# PIC32MZ2025DAR176 device description
Architecture: MIPS; Family: PIC32MZDA; Series: PIC32MZ
Registers are 32-bit, read-write, no defined reset value unless marked. A register's access mark holds for its fields unless they carry their own. Offsets are from the block's base; [hi:lo] are bit positions; {n}, {i} and the like mark numbered series; 'fields as' and 'values as' point back to an identical list.

## DDR
Instances: DDR 0x1f8e8000 in periph_indep
0x00 DDRTSEL — DDR Target Select Register
  [7:0] TSEL
0x04 DDRMINLIM — DDR Minimum Burst Limit Register
  [4:0] MINLIMIT
0x08 DDRRQPER — DDR Request Period Register
  [7:0] RQPER
0x0C DDRMINCMD — DDR Minimum Command Register
  [7:0] MINCMD
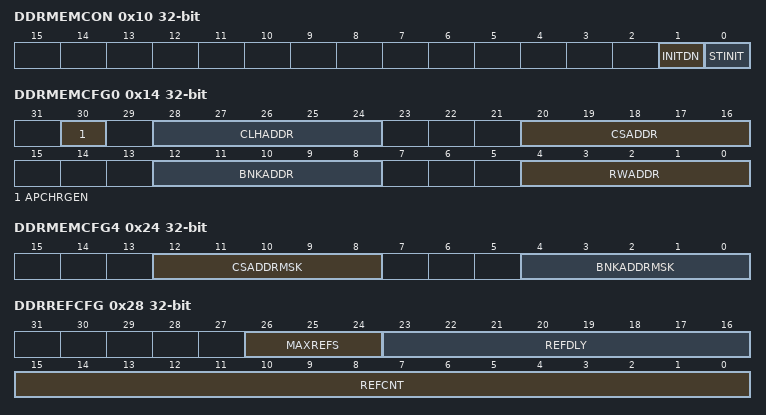
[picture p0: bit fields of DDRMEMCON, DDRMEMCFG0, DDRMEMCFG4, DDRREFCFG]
0x10 DDRMEMCON — DDR Memory Control Register
  [1] INITDN — Memory Initialize Done bit
    1=All commands have been issued; the controller is enabled for regular operation; 0=Controller not enabled for regular operation
  [0] STINIT — Memory Initialize Start bit
    1=Start memory initialization; 0=Do not start memory initialization
0x14 DDRMEMCFG0 — DDR Memory Configuration Register 0
  [30] APCHRGEN — Automatic Precharge Enable bit
    1=Issue an auto-precharged command; 0=Do not issue an auto-precharged command
  [28:24] CLHADDR
  [20:16] CSADDR
  [12:8] BNKADDR
  [4:0] RWADDR
0x18 DDRMEMCFG1 — DDR Memory Configuration Register 1
  [12:0] RWADDRMSK
0x1C DDRMEMCFG2 — DDR Memory Configuration Register 2
  [12:0] CLADDRHMSK
0x20 DDRMEMCFG3 — DDR Memory Configuration Register 3
  [12:0] CLADDRLMSK
0x24 DDRMEMCFG4 — DDR Memory Configuration Register 4
  [12:8] CSADDRMSK, [4:0] BNKADDRMSK
0x28 DDRREFCFG — DDR Refresh Configuration Register
  [26:24] MAXREFS, [23:16] REFDLY, [15:0] REFCNT
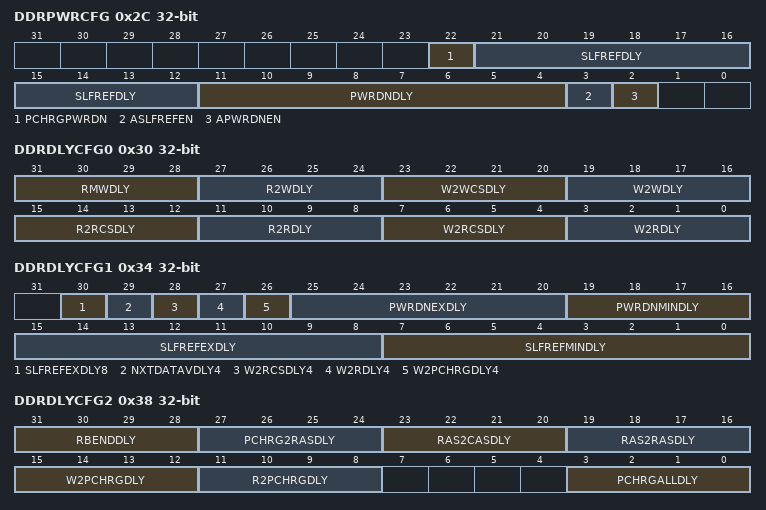
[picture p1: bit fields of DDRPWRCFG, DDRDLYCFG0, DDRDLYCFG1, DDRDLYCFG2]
0x2C DDRPWRCFG — DDR Power Configuration Register
  [22] PCHRGPWRDN — Precharge Power Down Only bit
    1=Allow automatic entry into Precharge Power Down mode; 0=Do not allow automatic entry into Precharge Power Down mode
  [21:12] SLFREFDLY — Self Refresh Delay bits
    0x1ff=2111452 clocks; 1=1024 clocks
  [11:4] PWRDNDLY — Refresh Count bits
    255=1020 clocks; 1=4 clocks
  [3] ASLFREFEN — Automatic Self Refresh Enable bit
    1=Allow automatic entry into Self Refresh mode; 0=Do not allow automatic entry into Self Refresh mode
  [2] APWRDNEN — Automatic Power Down Enable bit
    1=Allow automatic entry into Power Down mode; 0=Do not allow automatic entry into Power Down mode
0x30 DDRDLYCFG0 — DDR Delay Configuration Register 0
  [31:28] RMWDLY, [27:24] R2WDLY, [23:20] W2WCSDLY, [19:16] W2WDLY, [15:12] R2RCSDLY, [11:8] R2RDLY, [7:4] W2RCSDLY, [3:0] W2RDLY
0x34 DDRDLYCFG1 — DDR Delay Configuration Register 1
  [30] SLFREFEXDLY8, [29] NXTDATAVDLY4, [28] W2RCSDLY4, [27] W2RDLY4, [26] W2PCHRGDLY4, [25:20] PWRDNEXDLY, [19:16] PWRDNMINDLY, [15:8] SLFREFEXDLY, [7:0] SLFREFMINDLY
0x38 DDRDLYCFG2 — DDR Delay Configuration Register 2
  [31:28] RBENDDLY, [27:24] PCHRG2RASDLY, [23:20] RAS2CASDLY, [19:16] RAS2RASDLY, [15:12] W2PCHRGDLY, [11:8] R2PCHRGDLY, [3:0] PCHRGALLDLY
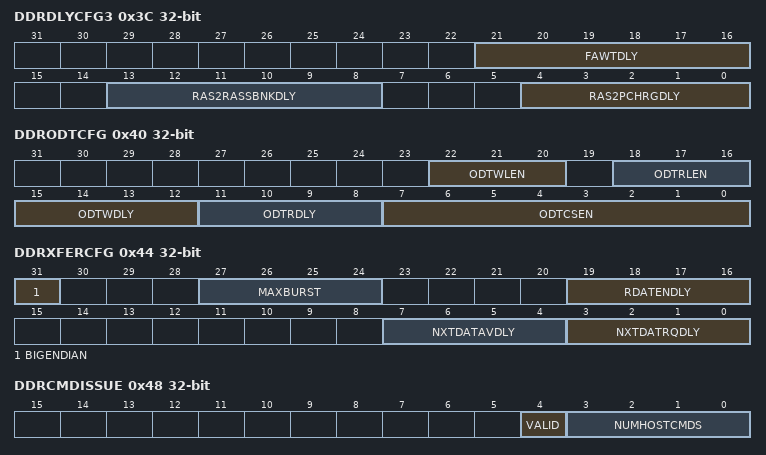
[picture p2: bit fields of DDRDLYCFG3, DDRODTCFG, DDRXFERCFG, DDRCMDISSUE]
0x3C DDRDLYCFG3 — DDR Delay Configuration Register 3
  [21:16] FAWTDLY, [13:8] RAS2RASSBNKDLY, [4:0] RAS2PCHRGDLY
0x40 DDRODTCFG — DDR On-Die Termination Configuration Register
  [22:20] ODTWLEN, [18:16] ODTRLEN, [15:12] ODTWDLY, [11:8] ODTRDLY, [7:0] ODTCSEN
0x44 DDRXFERCFG — DDR Transfer Configuration Register
  [31] BIGENDIAN — Big Endian bit
    1=Data is big endian format; 0=Data is little endian format
  [27:24] MAXBURST
  [19:16] RDATENDLY
  [7:4] NXTDATAVDLY
  [3:0] NXTDATRQDLY
0x48 DDRCMDISSUE — DDR Command Issue Register
  [4] VALID, [3:0] NUMHOSTCMDS
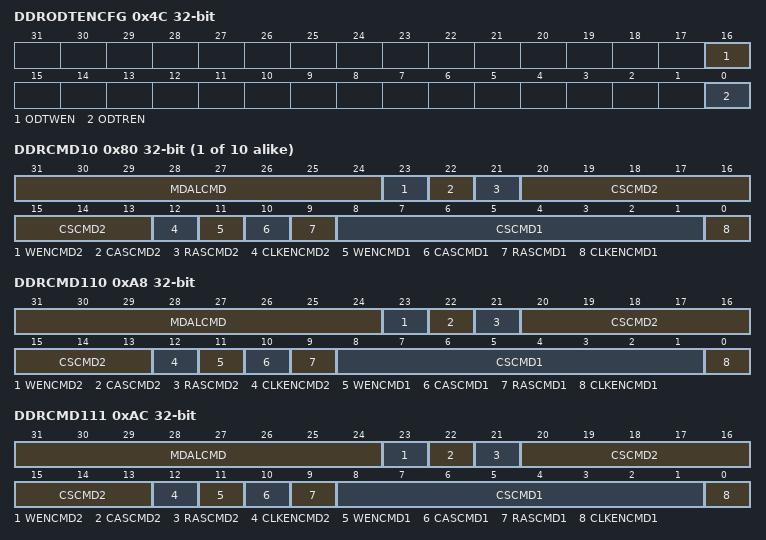
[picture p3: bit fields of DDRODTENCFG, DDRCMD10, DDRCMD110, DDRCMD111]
0x4C DDRODTENCFG — DDR On-Die Termination Enable Configuration Register
  [16] ODTWEN — On-Die Termination Write Enable bit
    1=The Chip Select represented by the OTDCSEN bits (DDRODTCFG<7:0>) has ODT enabled for data reads; 0=The Chip Select represented by the OTDCSEN bits (DDRODTCFG<7:0>) has ODT disabled for data reads
  [0] ODTREN — On-Die Termination Read Enable bit
    1=The Chip Select represented by the OTDCSEN bits (DDRODTCFG<7:0>) has ODT enabled for data writes; 0=The Chip Select represented by the OTDCSEN bits (DDRODTCFG<7:0>) has ODT disabled for data writes
0x50 DDRMEMWIDTH — DDR Memory Width Register
  [3] HALFRATE — Half-rate Mode bit
    1=Half-rate mode; 0=Full-rate mode
{0x58+4i} DDRCMD{i} (i=10..19) — DDR Host Command 1 Register x (x = 0 through 15)
  [31:24] MDALCMD, [23] WENCMD2, [22] CASCMD2, [21] RASCMD2, [20:13] CSCMD2, [12] CLKENCMD2, [11] WENCMD1, [10] CASCMD1, [9] RASCMD1, [8:1] CSCMD1, [0] CLKENCMD1
0xA8 DDRCMD110 — DDR Host Command 1 Register x (x = 0 through 15)
  fields as DDRCMD10
0xAC DDRCMD111 — DDR Host Command 1 Register x (x = 0 through 15)
  fields as DDRCMD10
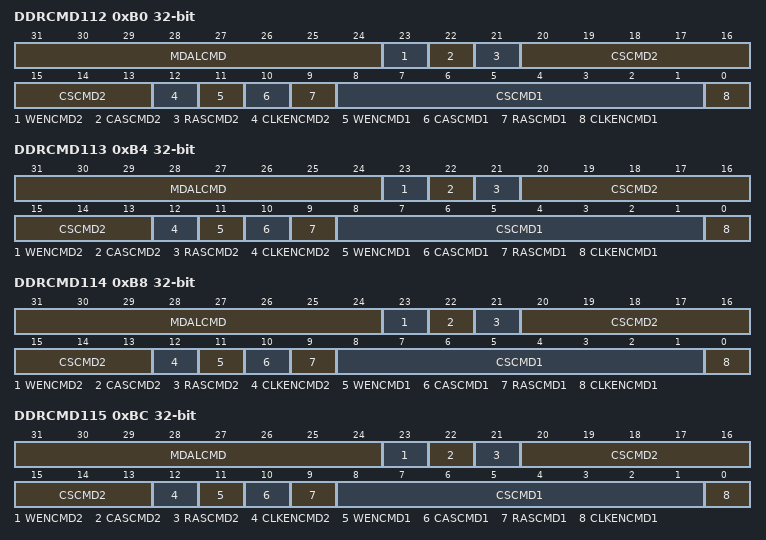
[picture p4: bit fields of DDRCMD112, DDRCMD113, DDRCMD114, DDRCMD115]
0xB0 DDRCMD112 — DDR Host Command 1 Register x (x = 0 through 15)
  fields as DDRCMD10
0xB4 DDRCMD113 — DDR Host Command 1 Register x (x = 0 through 15)
  fields as DDRCMD10
0xB8 DDRCMD114 — DDR Host Command 1 Register x (x = 0 through 15)
  fields as DDRCMD10
0xBC DDRCMD115 — DDR Host Command 1 Register x (x = 0 through 15)
  fields as DDRCMD10
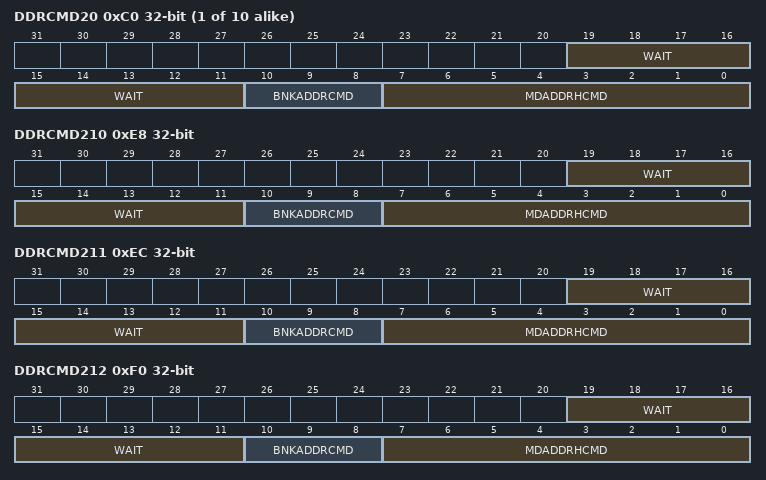
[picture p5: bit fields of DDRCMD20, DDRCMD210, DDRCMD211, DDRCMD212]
{0x70+4i} DDRCMD{i} (i=20..29) — DDR Host Command 2 Register x (x = 0 through 15)
  [19:11] WAIT, [10:8] BNKADDRCMD, [7:0] MDADDRHCMD
0xE8 DDRCMD210 — DDR Host Command 2 Register x (x = 0 through 15)
  [19:11] WAIT, [10:8] BNKADDRCMD, [7:0] MDADDRHCMD
0xEC DDRCMD211 — DDR Host Command 2 Register x (x = 0 through 15)
  [19:11] WAIT, [10:8] BNKADDRCMD, [7:0] MDADDRHCMD
0xF0 DDRCMD212 — DDR Host Command 2 Register x (x = 0 through 15)
  [19:11] WAIT, [10:8] BNKADDRCMD, [7:0] MDADDRHCMD
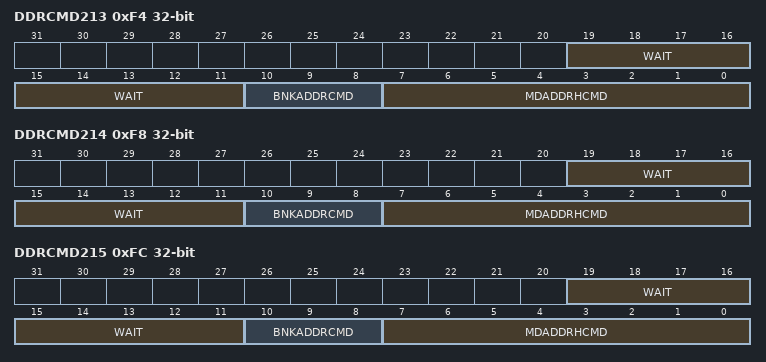
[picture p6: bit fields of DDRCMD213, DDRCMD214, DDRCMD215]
0xF4 DDRCMD213 — DDR Host Command 2 Register x (x = 0 through 15)
  [19:11] WAIT, [10:8] BNKADDRCMD, [7:0] MDADDRHCMD
0xF8 DDRCMD214 — DDR Host Command 2 Register x (x = 0 through 15)
  [19:11] WAIT, [10:8] BNKADDRCMD, [7:0] MDADDRHCMD
0xFC DDRCMD215 — DDR Host Command 2 Register x (x = 0 through 15)
  [19:11] WAIT, [10:8] BNKADDRCMD, [7:0] MDADDRHCMD

## Notices in the file
Copyright (c) 2017 Microchip Technology Inc.
SPDX-License-Identifier: Apache-2.0
Licensed under the Apache License, Version 2.0 (the "License");
you may not use this file except in compliance with the License.
You may obtain a copy of the License at
http://www.apache.org/licenses/LICENSE-2.0
Unless required by applicable law or agreed to in writing, software
distributed under the License is distributed on an "AS IS" BASIS,
WITHOUT WARRANTIES OR CONDITIONS OF ANY KIND, either express or implied.
See the License for the specific language governing permissions and
limitations under the License.
